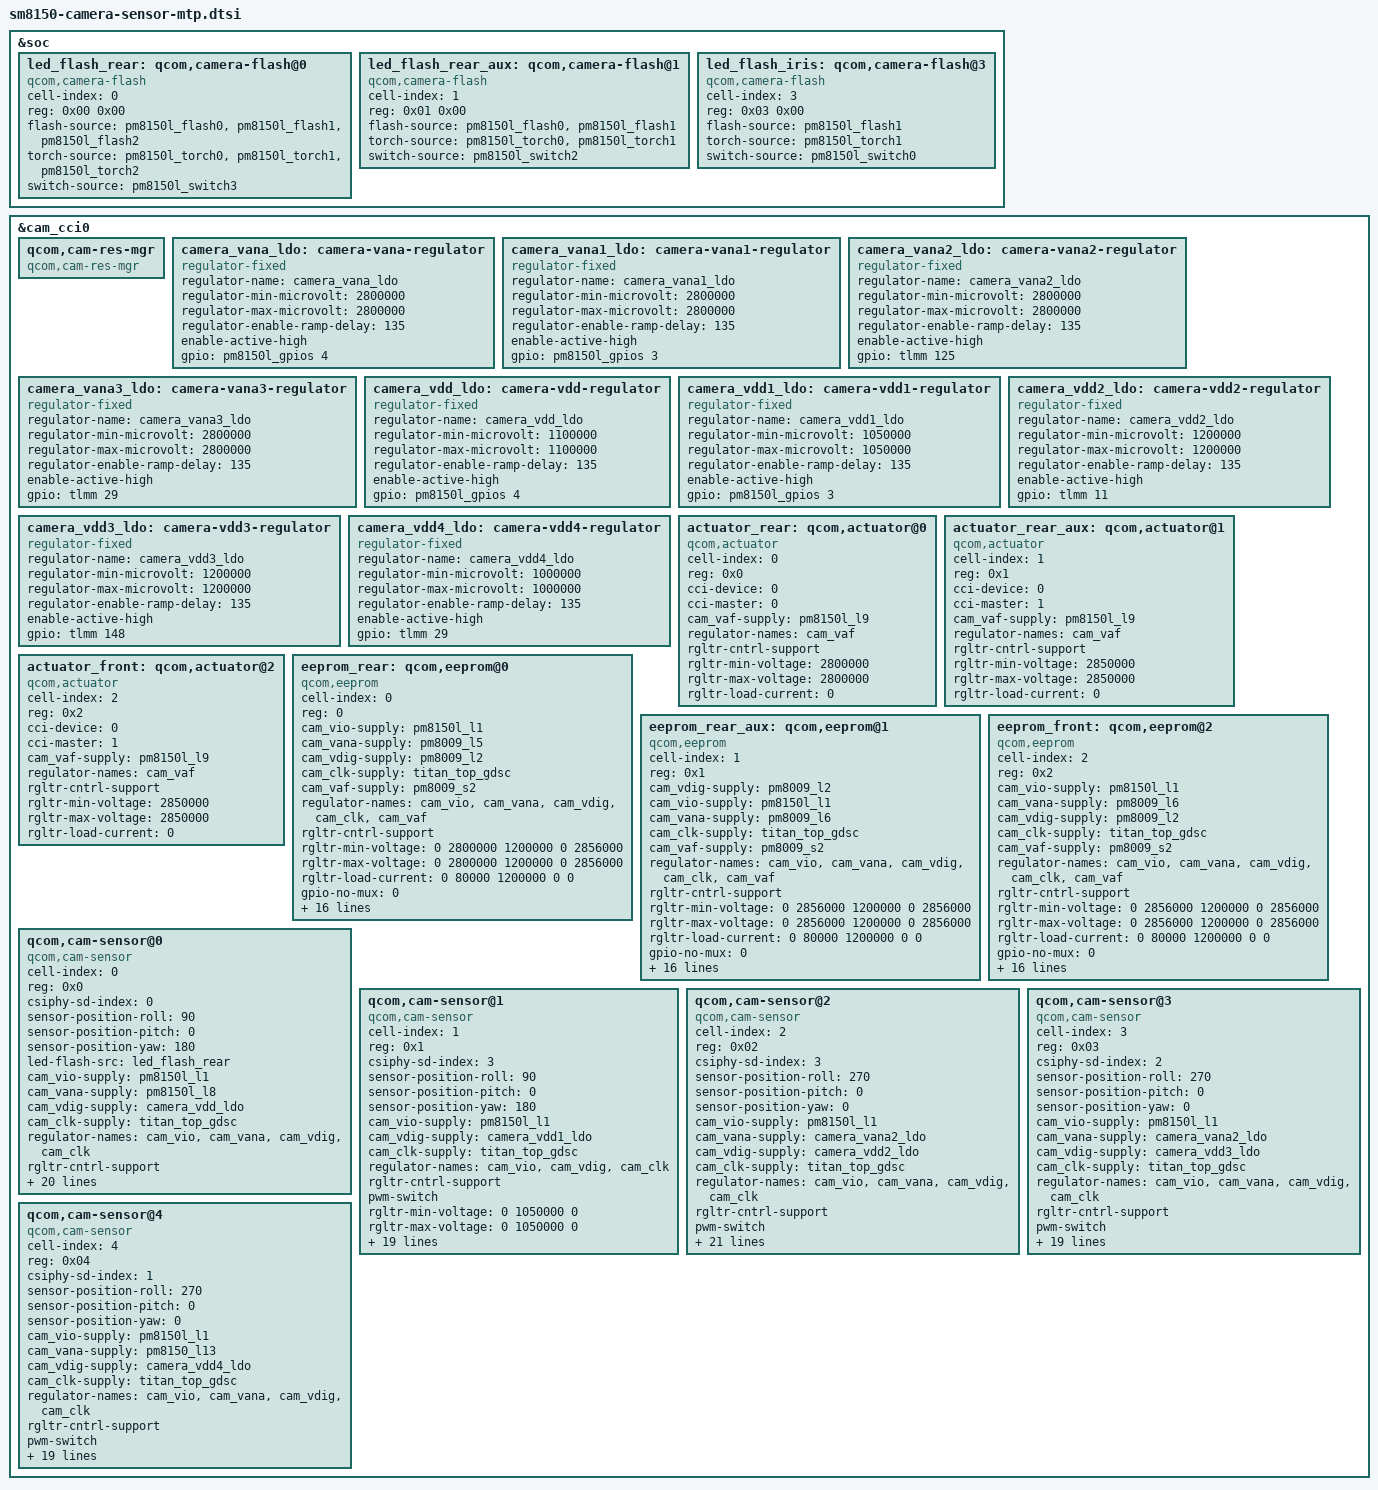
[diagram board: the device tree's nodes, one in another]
/*
 * Copyright (c) 2018, The Linux Foundation. All rights reserved.
 *
 * This program is free software; you can redistribute it and/or modify
 * it under the terms of the GNU General Public License version 2 and
 * only version 2 as published by the Free Software Foundation.
 *
 * This program is distributed in the hope that it will be useful,
 * but WITHOUT ANY WARRANTY; without even the implied warranty of
 * MERCHANTABILITY or FITNESS FOR A PARTICULAR PURPOSE.  See the
 * GNU General Public License for more details.
 */

#include <dt-bindings/clock/qcom,camcc-sm8150.h>

&soc {
	led_flash_rear: qcom,camera-flash@0 {
		cell-index = <0>;
		reg = <0x00 0x00>;
		compatible = "qcom,camera-flash";
		flash-source = <&pm8150l_flash0 &pm8150l_flash1 &pm8150l_flash2>;
		torch-source = <&pm8150l_torch0 &pm8150l_torch1 &pm8150l_torch2>;
		switch-source = <&pm8150l_switch3>;
		status = "ok";
	};

	led_flash_rear_aux: qcom,camera-flash@1 {
		cell-index = <1>;
		reg = <0x01 0x00>;
		compatible = "qcom,camera-flash";
		flash-source = <&pm8150l_flash0 &pm8150l_flash1>;
		torch-source = <&pm8150l_torch0 &pm8150l_torch1>;
		switch-source = <&pm8150l_switch2>;
		status = "ok";
	};

	led_flash_iris: qcom,camera-flash@3 {
		cell-index = <3>;
		reg = <0x03 0x00>;
		compatible = "qcom,camera-flash";
		flash-source = <&pm8150l_flash1>;
		torch-source = <&pm8150l_torch1>;
		switch-source = <&pm8150l_switch0>;
		status = "ok";
	};
};

&cam_cci0 {
	qcom,cam-res-mgr {
		compatible = "qcom,cam-res-mgr";
		status = "ok";
	};
	camera_vana_ldo: camera-vana-regulator {
		compatible = "regulator-fixed";
		regulator-name = "camera_vana_ldo";
		regulator-min-microvolt = <2800000>;
		regulator-max-microvolt = <2800000>;
		regulator-enable-ramp-delay = <135>; // Check
		enable-active-high;
		gpio = <&pm8150l_gpios 4 0>;
		/*pinctrl-names = "default";
		pinctrl-0 = <&cam_sensor_eldo4_default>;
		vin-supply = <&pm8150l_bob>;*/
	};
	camera_vana1_ldo: camera-vana1-regulator {
		compatible = "regulator-fixed";
		regulator-name = "camera_vana1_ldo";
		regulator-min-microvolt = <2800000>;
		regulator-max-microvolt = <2800000>;
		regulator-enable-ramp-delay = <135>; // Check
		enable-active-high;
		gpio = <&pm8150l_gpios 3 0>;
		/*pinctrl-names = "default";
		pinctrl-0 = <&cam_sensor_eldo3_default>;
		vin-supply = <&pm8150l_bob>;*/
	};
	camera_vana2_ldo: camera-vana2-regulator {
		compatible = "regulator-fixed";
		regulator-name = "camera_vana2_ldo";
		regulator-min-microvolt = <2800000>;
		regulator-max-microvolt = <2800000>;
		regulator-enable-ramp-delay = <135>; // Check
		enable-active-high;
		gpio = <&tlmm 125 0>;
		/*pinctrl-names = "default";
		pinctrl-0 = <&camera_vana_en_default>;
		vin-supply = <&pm8150l_bob>;*/
	};

	camera_vana3_ldo: camera-vana3-regulator {
		compatible = "regulator-fixed";
		regulator-name = "camera_vana3_ldo";
		regulator-min-microvolt = <2800000>;
		regulator-max-microvolt = <2800000>;
		regulator-enable-ramp-delay = <135>; // Check
		enable-active-high;
		gpio = <&tlmm 29 0>;
		/*pinctrl-names = "default";
		pinctrl-0 = <&camera_vana_en_default>;
		vin-supply = <&pm8150l_bob>;*/
	};

	camera_vdd_ldo: camera-vdd-regulator {
		compatible = "regulator-fixed";
		regulator-name = "camera_vdd_ldo";
		regulator-min-microvolt = <1100000>;
		regulator-max-microvolt = <1100000>;
		regulator-enable-ramp-delay = <135>; // Check
		enable-active-high;
		gpio = <&pm8150l_gpios 4 0>;
		/*pinctrl-names = "default";
		pinctrl-0 = <&cam_sensor_eldo4_default>;*/
	};
 	camera_vdd1_ldo: camera-vdd1-regulator {
		compatible = "regulator-fixed";
		regulator-name = "camera_vdd1_ldo";
		regulator-min-microvolt = <1050000>;
		regulator-max-microvolt = <1050000>;
		regulator-enable-ramp-delay = <135>; // Check
		enable-active-high;
		gpio = <&pm8150l_gpios 3 0>;
		/*pinctrl-names = "default";
		pinctrl-0 = <&cam_sensor_eldo3_default>;*/
	};
	camera_vdd2_ldo: camera-vdd2-regulator {
		compatible = "regulator-fixed";
		regulator-name = "camera_vdd2_ldo";
		regulator-min-microvolt = <1200000>;
		regulator-max-microvolt = <1200000>;
		regulator-enable-ramp-delay = <135>; // Check
		enable-active-high;
		gpio = <&tlmm 11 0>;
	/*	pinctrl-names = "default";
		pinctrl-0 = <&camera_vadd2_en_default>;
		vin-supply = <&pm8150_s5>;*/
	};    
	camera_vdd3_ldo: camera-vdd3-regulator {
		compatible = "regulator-fixed";
		regulator-name = "camera_vdd3_ldo";
		regulator-min-microvolt = <1200000>;
		regulator-max-microvolt = <1200000>;
		regulator-enable-ramp-delay = <135>; // Check
		enable-active-high;
		gpio = <&tlmm 148 0>;
		/*pinctrl-names = "default";
		pinctrl-0 = <&camera_vdd3_en_default>;*/
	};
	camera_vdd4_ldo: camera-vdd4-regulator {
		compatible = "regulator-fixed";
		regulator-name = "camera_vdd4_ldo";
		regulator-min-microvolt = <1000000>;
		regulator-max-microvolt = <1000000>;
		regulator-enable-ramp-delay = <135>; // Check
		enable-active-high;
		gpio = <&tlmm 29 0>;
		/*pinctrl-names = "default";
		pinctrl-0 = <&camera_vdd4_en_default>;*/
	};

	actuator_rear: qcom,actuator@0 {
		cell-index = <0>;
		reg = <0x0>;
		compatible = "qcom,actuator";
		cci-device = <0>;
		cci-master = <0>;
		cam_vaf-supply = <&pm8150l_l9>;
		regulator-names = "cam_vaf";
		rgltr-cntrl-support;
		rgltr-min-voltage = <2800000>;
		rgltr-max-voltage = <2800000>;
		rgltr-load-current = <0>;
	};

	actuator_rear_aux: qcom,actuator@1 {
		cell-index = <1>;
		reg = <0x1>;
		compatible = "qcom,actuator";
		cci-device = <0>;
		cci-master = <1>;
		cam_vaf-supply = <&pm8150l_l9>;
		regulator-names = "cam_vaf";
		rgltr-cntrl-support;
		rgltr-min-voltage = <2850000>;
		rgltr-max-voltage = <2850000>;
		rgltr-load-current = <0>;
	};

	actuator_front: qcom,actuator@2 {
		cell-index = <2>;
		reg = <0x2>;
		compatible = "qcom,actuator";
		cci-device = <0>;
		cci-master = <1>;
		cam_vaf-supply = <&pm8150l_l9>;
		regulator-names = "cam_vaf";
		rgltr-cntrl-support;
		rgltr-min-voltage = <2850000>;
		rgltr-max-voltage = <2850000>;
		rgltr-load-current = <0>;
	};

	eeprom_rear: qcom,eeprom@0 {
		cell-index = <0>;
		reg = <0>;
		compatible = "qcom,eeprom";
		cam_vio-supply = <&pm8150l_l1>;
		cam_vana-supply = <&pm8009_l5>;
		cam_vdig-supply = <&pm8009_l2>;
		cam_clk-supply = <&titan_top_gdsc>;
		cam_vaf-supply = <&pm8009_s2>;
		regulator-names = "cam_vio", "cam_vana", "cam_vdig",
			"cam_clk", "cam_vaf";
		rgltr-cntrl-support;
		rgltr-min-voltage = <0 2800000 1200000 0 2856000>;
		rgltr-max-voltage = <0 2800000 1200000 0 2856000>;
		rgltr-load-current = <0 80000 1200000 0 0>;
		gpio-no-mux = <0>;
		pinctrl-names = "cam_default", "cam_suspend";
		pinctrl-0 = <&cam_sensor_mclk0_active
				&cam_sensor_active_rear>;
		pinctrl-1 = <&cam_sensor_mclk0_suspend
				&cam_sensor_suspend_rear>;
		gpios = <&tlmm 13 0>,
			<&tlmm 28 0>;
		gpio-reset = <1>;
		gpio-req-tbl-num = <0 1>;
		gpio-req-tbl-flags = <1 0>;
		gpio-req-tbl-label = "CAMIF_MCLK0",
					"CAM_RESET0";
		sensor-position = <0>;
		sensor-mode = <0>;
		cci-device = <0>;
		cci-master = <0>;
		status = "ok";
		clocks = <&clock_camcc CAM_CC_MCLK0_CLK>;
		clock-names = "cam_clk";
		clock-cntl-level = "turbo";
		clock-rates = <24000000>;
	};

	eeprom_rear_aux: qcom,eeprom@1 {
		cell-index = <1>;
		reg = <0x1>;
		compatible = "qcom,eeprom";
		cam_vdig-supply = <&pm8009_l2>;
		cam_vio-supply = <&pm8150l_l1>;
		cam_vana-supply = <&pm8009_l6>;
		cam_clk-supply = <&titan_top_gdsc>;
		cam_vaf-supply = <&pm8009_s2>;
		regulator-names = "cam_vio", "cam_vana", "cam_vdig",
			"cam_clk", "cam_vaf";
		rgltr-cntrl-support;
		rgltr-min-voltage = <0 2856000 1200000 0 2856000>;
		rgltr-max-voltage = <0 2856000 1200000 0 2856000>;
		rgltr-load-current = <0 80000 1200000 0 0>;
		gpio-no-mux = <0>;
		pinctrl-names = "cam_default", "cam_suspend";
		pinctrl-0 = <&cam_sensor_mclk1_active
				 &cam_sensor_active_rear_aux>;
		pinctrl-1 = <&cam_sensor_mclk1_suspend
				 &cam_sensor_suspend_rear_aux>;
		gpios = <&tlmm 14 0>,
			<&tlmm 30 0>;
		gpio-reset = <1>;
		gpio-req-tbl-num = <0 1>;
		gpio-req-tbl-flags = <1 0>;
		gpio-req-tbl-label = "CAMIF_MCLK1",
					"CAM_RESET1";
		sensor-position = <0>;
		sensor-mode = <0>;
		cci-device = <0>;
		cci-master = <1>;
		status = "ok";
		clocks = <&clock_camcc CAM_CC_MCLK2_CLK>;
		clock-names = "cam_clk";
		clock-cntl-level = "turbo";
		clock-rates = <24000000>;
	};

	eeprom_front: qcom,eeprom@2 {
		cell-index = <2>;
		reg = <0x2>;
		compatible = "qcom,eeprom";
		cam_vio-supply = <&pm8150l_l1>;
		cam_vana-supply = <&pm8009_l6>;
		cam_vdig-supply = <&pm8009_l2>;
		cam_clk-supply = <&titan_top_gdsc>;
		cam_vaf-supply = <&pm8009_s2>;
		regulator-names = "cam_vio", "cam_vana", "cam_vdig",
			"cam_clk", "cam_vaf";
		rgltr-cntrl-support;
		rgltr-min-voltage = <0 2856000 1200000 0 2856000>;
		rgltr-max-voltage = <0 2856000 1200000 0 2856000>;
		rgltr-load-current = <0 80000 1200000 0 0>;
		gpio-no-mux = <0>;
		pinctrl-names = "cam_default", "cam_suspend";
		pinctrl-0 = <&cam_sensor_mclk2_active
				 &cam_sensor_active_front>;
		pinctrl-1 = <&cam_sensor_mclk2_suspend
				 &cam_sensor_suspend_front>;
		gpios = <&tlmm 15 0>,
			<&tlmm 12 0>;
		gpio-reset = <1>;
		gpio-req-tbl-num = <0 1>;
		gpio-req-tbl-flags = <1 0>;
		gpio-req-tbl-label = "CAMIF_MCLK2",
					"CAM_RESET2";
		sensor-position = <1>;
		sensor-mode = <0>;
		cci-device = <1>;
		cci-master = <0>;
		status = "ok";
		clocks = <&clock_camcc CAM_CC_MCLK2_CLK>;
		clock-names = "cam_clk";
		clock-cntl-level = "turbo";
		clock-rates = <24000000>;
	};
    /*imx586 48M*/
	qcom,cam-sensor@0 {
		cell-index = <0>;
		compatible = "qcom,cam-sensor";
		reg = <0x0>;
		csiphy-sd-index = <0>;
		sensor-position-roll = <90>;
		sensor-position-pitch = <0>;
		sensor-position-yaw = <180>;
		led-flash-src = <&led_flash_rear>;
		/*actuator-src = <&actuator_rear>;
		ois-src = <&ois_rear>;
		eeprom-src = <&eeprom_rear>;
		 */
		cam_vio-supply = <&pm8150l_l1>;
		cam_vana-supply = <&pm8150l_l8>;
		cam_vdig-supply = <&camera_vdd_ldo>;
		cam_clk-supply = <&titan_top_gdsc>;
		regulator-names = "cam_vio", "cam_vana", "cam_vdig",
			"cam_clk";
		rgltr-cntrl-support;
        pwm-switch;
		rgltr-min-voltage = <0 1800000 1100000 0>;
		rgltr-max-voltage = <0 1800000 1100000 0>;
		rgltr-load-current = <0 180000 1100000 0>;
		gpio-no-mux = <0>;
		pinctrl-names = "cam_default", "cam_suspend";
		pinctrl-0 = <&cam_sensor_mclk1_active
				&cam_sensor_active_camera>;
		pinctrl-1 = <&cam_sensor_mclk1_suspend
				&cam_sensor_suspend_camera>;
		gpios = <&tlmm 14 0>,
			<&tlmm 30 0>;
		gpio-reset = <1>;
		gpio-req-tbl-num = <0 1>;
		gpio-req-tbl-flags = <1 0>;
		gpio-req-tbl-label = "CAMIF_MCLK1",
					"CAM_RESET1";
		sensor-mode = <0>;
		cci-device = <0>;
		cci-master = <1>;
		status = "ok";
		clocks = <&clock_camcc CAM_CC_MCLK1_CLK>;
		clock-names = "cam_clk";
		clock-cntl-level = "turbo";
		clock-rates = <19200000>;
	};

    /*3t1 20M*/
	qcom,cam-sensor@1 {
		cell-index = <1>;
		compatible = "qcom,cam-sensor";
		reg = <0x1>;
		csiphy-sd-index = <3>;
		sensor-position-roll = <90>;
		sensor-position-pitch = <0>;
		sensor-position-yaw = <180>;
		/*led-flash-src = <&led_flash_rear>;
		actuator-src = <&actuator_rear>;
		ois-src = <&ois_rear>;
		eeprom-src = <&eeprom_rear>;
		 */
		cam_vio-supply = <&pm8150l_l1>;
		cam_vdig-supply = <&camera_vdd1_ldo>;
		cam_clk-supply = <&titan_top_gdsc>;
		regulator-names = "cam_vio", "cam_vdig",
			"cam_clk";
		rgltr-cntrl-support;
        pwm-switch;
		rgltr-min-voltage = <0 1050000 0>;
		rgltr-max-voltage = <0 1050000 0>;
		rgltr-load-current = <0 1050000 0>;
		gpio-no-mux = <0>;
		pinctrl-names = "cam_default", "cam_suspend";
		pinctrl-0 = <&cam_sensor_mclk0_active
				&cam_sensor_active_camera1>;
		pinctrl-1 = <&cam_sensor_mclk0_suspend
				&cam_sensor_suspend_camera1>;
		gpios = <&tlmm 13 0>,
			<&tlmm 28 0>,
			<&tlmm 42 0>;
		gpio-reset = <1>;
		gpio-custom1 = <2>;
		gpio-req-tbl-num = <0 1 2>;
		gpio-req-tbl-flags = <1 0 2>;
		gpio-req-tbl-label = "CAMIF_MCLK0",
					"CAM_RESET0",
					"CAM_SWITCH_CSI";
		sensor-mode = <0>;
		cci-device = <0>;
		cci-master = <0>;
		status = "ok";
		clocks = <&clock_camcc CAM_CC_MCLK0_CLK>;
		clock-names = "cam_clk";
		clock-cntl-level = "turbo";
		clock-rates = <19200000>;
	};

    /*5e9 5M*/
	qcom,cam-sensor@2 {
		cell-index = <2>;
		compatible = "qcom,cam-sensor";
		reg = <0x02>;
		csiphy-sd-index = <3>;
		sensor-position-roll = <270>;
		sensor-position-pitch = <0>;
		sensor-position-yaw = <0>;
	/*	eeprom-src = <&eeprom_front>;
		actuator-src = <&actuator_front>;*/
		cam_vio-supply = <&pm8150l_l1>;
		cam_vana-supply = <&camera_vana2_ldo>;
		cam_vdig-supply = <&camera_vdd2_ldo>;
		cam_clk-supply = <&titan_top_gdsc>;
		regulator-names = "cam_vio", "cam_vana", "cam_vdig",
			"cam_clk";
		rgltr-cntrl-support;
        pwm-switch;
		rgltr-min-voltage = <0 2800000 1200000 0>;
		rgltr-max-voltage = <0 2800000 1200000 0>;
		rgltr-load-current = <0 80000 1200000 0>;
		gpio-no-mux = <0>;
		pinctrl-names = "cam_default", "cam_suspend";
		pinctrl-0 = <&cam_sensor_mclk0_active
				&cam_sensor_active_camera2>;
		pinctrl-1 = <&cam_sensor_mclk0_suspend
				&cam_sensor_suspend_camera2>;
		gpios = <&tlmm 13 0>,
			<&tlmm 25 0>,
			<&tlmm 42 0>;
		gpio-reset = <1>;
		gpio-custom1 = <2>;
		gpio-req-tbl-num = <0 1 2>;
		gpio-req-tbl-flags = <1 0 2>;
		gpio-req-tbl-label = "CAMIF_MCLK0",
					"CAM_RESET0",
					"CAM_SWITCH_CSI";
		sensor-mode = <0>;
		cci-device = <0>;
		cci-master = <0>;
		status = "ok";
		clocks = <&clock_camcc CAM_CC_MCLK0_CLK>;
		clock-names = "cam_clk";
		clock-cntl-level = "turbo";
		clock-rates = <19200000>;
	};

    /*ov8856 8M*/
	qcom,cam-sensor@3 {
		cell-index = <3>;
		compatible = "qcom,cam-sensor";
		reg = <0x03>;
		csiphy-sd-index = <2>;
		sensor-position-roll = <270>;
		sensor-position-pitch = <0>;
		sensor-position-yaw = <0>;
		/*led-flash-src = <&led_flash_iris>;*/
		cam_vio-supply = <&pm8150l_l1>;
		cam_vana-supply = <&camera_vana2_ldo>;
		cam_vdig-supply = <&camera_vdd3_ldo>;
		cam_clk-supply = <&titan_top_gdsc>;
		regulator-names = "cam_vio", "cam_vana", "cam_vdig",
			"cam_clk";
		rgltr-cntrl-support;
        pwm-switch;
		rgltr-min-voltage = <0 2800000 1200000 0>;
		rgltr-max-voltage = <0 2800000 1200000 0>;
		rgltr-load-current = <0 80000 1200000 0>;
		gpio-no-mux = <0>;
		pinctrl-names = "cam_default", "cam_suspend";
		pinctrl-0 = <&cam_sensor_mclk2_active
				&cam_sensor_active_camera3>;
		pinctrl-1 = <&cam_sensor_mclk2_suspend
				&cam_sensor_suspend_camera3>;
		gpios = <&tlmm 15 0>,
			<&tlmm 12 0>;
		gpio-reset = <1>;
		gpio-req-tbl-num = <0 1>;
		gpio-req-tbl-flags = <1 0>;
		gpio-req-tbl-label = "CAMIF_MCLK2",
					"CAM_RESET2";
		sensor-mode = <0>;
		cci-device = <1>;
		cci-master = <0>;
		status = "ok";
		clocks = <&clock_camcc CAM_CC_MCLK2_CLK>;
		clock-names = "cam_clk";
		clock-cntl-level = "turbo";
		clock-rates = <19200000>;
	};

    /*3l6 13M*/
	qcom,cam-sensor@4 {
		cell-index = <4>;
		compatible = "qcom,cam-sensor";
		reg = <0x04>;
		csiphy-sd-index = <1>;
		sensor-position-roll = <270>;
		sensor-position-pitch = <0>;
		sensor-position-yaw = <0>;
		/*led-flash-src = <&led_flash_iris>;*/
		cam_vio-supply = <&pm8150l_l1>;
		cam_vana-supply = <&pm8150_l13>;
		cam_vdig-supply = <&camera_vdd4_ldo>;
		cam_clk-supply = <&titan_top_gdsc>;
		regulator-names = "cam_vio", "cam_vana", "cam_vdig",
			"cam_clk";
		rgltr-cntrl-support;
        pwm-switch;
		rgltr-min-voltage = <0 2700000 1000000 0>;
		rgltr-max-voltage = <0 2800000 1000000 0>;
		rgltr-load-current = <0 80000 1000000 0>;
		gpio-no-mux = <0>;
		pinctrl-names = "cam_default", "cam_suspend";
		pinctrl-0 = <&cam_sensor_mclk3_active
				&cam_sensor_active_camera4>;
		pinctrl-1 = <&cam_sensor_mclk3_suspend
				&cam_sensor_suspend_camera4>;
		gpios = <&tlmm 16 0>,
			<&tlmm 23 0>;
		gpio-reset = <1>;
		gpio-req-tbl-num = <0 1>;
		gpio-req-tbl-flags = <1 0>;
		gpio-req-tbl-label = "CAMIF_MCLK3",
					"CAM_RESET3";
		sensor-mode = <0>;
		cci-device = <1>;
		cci-master = <0>;
		status = "ok";
		clocks = <&clock_camcc CAM_CC_MCLK3_CLK>;
		clock-names = "cam_clk";
		clock-cntl-level = "turbo";
		clock-rates = <19200000>;
	};    
};
